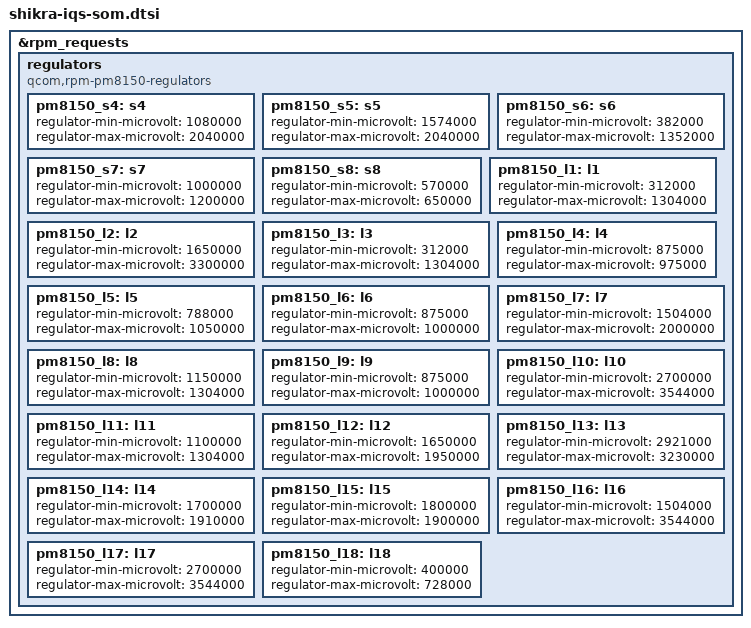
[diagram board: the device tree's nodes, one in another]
// SPDX-License-Identifier: BSD-3-Clause
/*
 * Copyright (c) Qualcomm Technologies, Inc. and/or its subsidiaries.
 */

#include "shikra.dtsi"

/* APQ (No Modem), Wailua PMIC */
&rpm_requests {
	regulators {
		compatible = "qcom,rpm-pm8150-regulators";

		pm8150_s4: s4 {
			regulator-min-microvolt = <1080000>;
			regulator-max-microvolt = <2040000>;
		};

		pm8150_s5: s5 {
			regulator-min-microvolt = <1574000>;
			regulator-max-microvolt = <2040000>;
		};

		pm8150_s6: s6 {
			regulator-min-microvolt = <382000>;
			regulator-max-microvolt = <1352000>;
		};

		pm8150_s7: s7 {
			regulator-min-microvolt = <1000000>;
			regulator-max-microvolt = <1200000>;
		};

		pm8150_s8: s8 {
			regulator-min-microvolt = <570000>;
			regulator-max-microvolt = <650000>;
		};

		pm8150_l1: l1 {
			regulator-min-microvolt = <312000>;
			regulator-max-microvolt = <1304000>;
		};

		pm8150_l2: l2 {
			regulator-min-microvolt = <1650000>;
			regulator-max-microvolt = <3300000>;
		};

		pm8150_l3: l3 {
			regulator-min-microvolt = <312000>;
			regulator-max-microvolt = <1304000>;
		};

		pm8150_l4: l4 {
			regulator-min-microvolt = <875000>;
			regulator-max-microvolt = <975000>;
		};

		pm8150_l5: l5 {
			regulator-min-microvolt = <788000>;
			regulator-max-microvolt = <1050000>;
		};

		pm8150_l6: l6 {
			regulator-min-microvolt = <875000>;
			regulator-max-microvolt = <1000000>;
		};

		pm8150_l7: l7 {
			regulator-min-microvolt = <1504000>;
			regulator-max-microvolt = <2000000>;
		};

		pm8150_l8: l8 {
			regulator-min-microvolt = <1150000>;
			regulator-max-microvolt = <1304000>;
		};

		pm8150_l9: l9 {
			regulator-min-microvolt = <875000>;
			regulator-max-microvolt = <1000000>;
		};

		pm8150_l10:l10{
			regulator-min-microvolt = <2700000>;
			regulator-max-microvolt = <3544000>;
		};

		pm8150_l11:l11{
			regulator-min-microvolt = <1100000>;
			regulator-max-microvolt = <1304000>;
		};

		pm8150_l12:l12{
			regulator-min-microvolt = <1650000>;
			regulator-max-microvolt = <1950000>;
		};

		pm8150_l13:l13{
			regulator-min-microvolt = <2921000>;
			regulator-max-microvolt = <3230000>;
		};

		pm8150_l14:l14{
			regulator-min-microvolt = <1700000>;
			regulator-max-microvolt = <1910000>;
		};

		pm8150_l15:l15{
			regulator-min-microvolt = <1800000>;
			regulator-max-microvolt = <1900000>;
		};

		pm8150_l16:l16{
			regulator-min-microvolt = <1504000>;
			regulator-max-microvolt = <3544000>;
		};

		pm8150_l17:l17{
			regulator-min-microvolt = <2700000>;
			regulator-max-microvolt = <3544000>;
		};

		pm8150_l18:l18{
			regulator-min-microvolt = <400000>;
			regulator-max-microvolt = <728000>;
		};
	};
};
